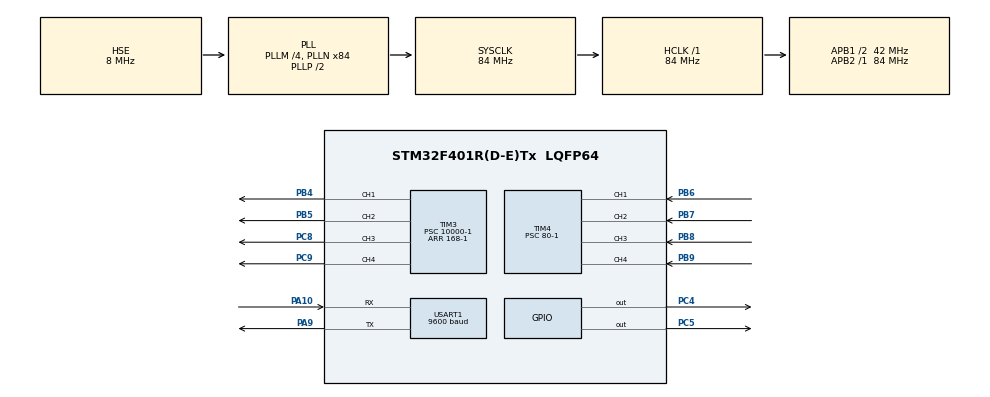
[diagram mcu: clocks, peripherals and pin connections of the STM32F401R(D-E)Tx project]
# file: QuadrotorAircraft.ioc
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Mcu.Family=STM32F4
Mcu.Name=STM32F401R(D-E)Tx
Mcu.Package=LQFP64
NVIC.PriorityGroup=NVIC_PRIORITYGROUP_4
NVIC.TIM4_IRQn=true\:0\:0\:false\:false\:true\:true\:true\:true
NVIC.USART1_IRQn=true\:0\:0\:false\:false\:true\:true\:true\:true
PA10.Mode=Asynchronous
PA10.Signal=USART1_RX
PA13.Mode=Serial_Wire
PA13.Signal=SYS_JTMS-SWDIO
PA14.Mode=Serial_Wire
PA14.Signal=SYS_JTCK-SWCLK
PA9.Mode=Asynchronous
PA9.Signal=USART1_TX
PB4.Signal=S_TIM3_CH1
PB5.Signal=S_TIM3_CH2
PB6.Signal=S_TIM4_CH1
PB7.Signal=S_TIM4_CH2
PB8.Signal=S_TIM4_CH3
PB9.Signal=S_TIM4_CH4
PC4.Signal=GPIO_Output
PC5.Signal=GPIO_Output
PC8.Signal=S_TIM3_CH3
PC9.Signal=S_TIM3_CH4
PH0\ -\ OSC_IN.Mode=HSE-External-Oscillator
PH0\ -\ OSC_IN.Signal=RCC_OSC_IN
PH1\ -\ OSC_OUT.Mode=HSE-External-Oscillator
PH1\ -\ OSC_OUT.Signal=RCC_OSC_OUT
ProjectManager.HeapSize=0x200
ProjectManager.StackSize=0x400
ProjectManager.TargetToolchain=MDK-ARM V5.32
RCC.48MHZClocksFreq_Value=42000000
RCC.AHBFreq_Value=84000000
RCC.APB1CLKDivider=RCC_HCLK_DIV2
RCC.APB1Freq_Value=42000000
RCC.APB1TimFreq_Value=84000000
RCC.APB2Freq_Value=84000000
RCC.APB2TimFreq_Value=84000000
RCC.CortexFreq_Value=84000000
RCC.HCLKFreq_Value=84000000
RCC.HSE_VALUE=8000000
RCC.HSI_VALUE=16000000
RCC.LSE_VALUE=32768
RCC.PLLM=4
RCC.PLLN=84
RCC.PLLSourceVirtual=RCC_PLLSOURCE_HSE
RCC.SYSCLKFreq_VALUE=84000000
RCC.SYSCLKSource=RCC_SYSCLKSOURCE_PLLCLK
RCC.VCOOutputFreq_Value=168000000
SH.S_TIM3_CH1.0=TIM3_CH1,PWM Generation1 CH1
SH.S_TIM3_CH2.0=TIM3_CH2,PWM Generation2 CH2
SH.S_TIM3_CH3.0=TIM3_CH3,PWM Generation3 CH3
SH.S_TIM3_CH4.0=TIM3_CH4,PWM Generation4 CH4
SH.S_TIM4_CH1.0=TIM4_CH1,Input_Capture1_from_TI1
SH.S_TIM4_CH2.0=TIM4_CH2,Input_Capture2_from_TI2
SH.S_TIM4_CH3.0=TIM4_CH3,Input_Capture3_from_TI3
SH.S_TIM4_CH4.0=TIM4_CH4,Input_Capture4_from_TI4
TIM3.Channel-PWM\ Generation1\ CH1=TIM_CHANNEL_1
TIM3.Channel-PWM\ Generation2\ CH2=TIM_CHANNEL_2
TIM3.Channel-PWM\ Generation3\ CH3=TIM_CHANNEL_3
TIM3.Channel-PWM\ Generation4\ CH4=TIM_CHANNEL_4
TIM3.Period=168-1
TIM3.Prescaler=10000-1
TIM4.Channel-Input_Capture1_from_TI1=TIM_CHANNEL_1
TIM4.Channel-Input_Capture2_from_TI2=TIM_CHANNEL_2
TIM4.Channel-Input_Capture3_from_TI3=TIM_CHANNEL_3
TIM4.Channel-Input_Capture4_from_TI4=TIM_CHANNEL_4
TIM4.Prescaler=80-1
USART1.BaudRate=9600
USART1.VirtualMode=VM_ASYNC
board=custom

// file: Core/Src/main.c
/* USER CODE BEGIN Header */
/**
  ******************************************************************************
  * @file           : main.c
  * @brief          : Main program body
  ******************************************************************************
  * @attention
  *
  * Copyright (c) 2024 STMicroelectronics.
  * All rights reserved.
  *
  * This software is licensed under terms that can be found in the LICENSE file
  * in the root directory of this software component.
  * If no LICENSE file comes with this software, it is provided AS-IS.
  *
  ******************************************************************************
  */
/* USER CODE END Header */
#include "main.h"
#include "tim.h"
#include "usart.h"
#include "gpio.h"

/* USER CODE BEGIN Includes */
#include "MySerial.h"
#include "MPU6050.h"
#include "Anonymity.h"
#include "AttitudeSolver.h"
#include "MadgWick.h"
#include "MyMadgWick.h"
#include "Motor.h"
#include "Receiver.h"
#include "UpdateMotorState.h"
#include "AttitudePIDController.h"

#include "tinyOS.h"
/* USER CODE END Includes */

/* USER CODE BEGIN PV */
extern quaternion q;
/* USER CODE END PV */

void SystemClock_Config(void);

tTask tTaskIdle;
tTaskStack idleTaskEnv[TINYOS_IDLETASK_STACK_SIZE];

void idleTaskEntry (void * param) {

#if TINYOS_ENABLE_CPUUSAGE_STATE == 1
    // 禁止调度，防止后面在创建任务时切换到其它任务中去
    tTaskSchedDisable();
#endif

    // 初始化App相关配置
    tInitApp();

#if TINYOS_ENABLE_TIMER == 1
    // 初始化定时器任务
    tTimerInitTask();
#endif

    // 启动系统时钟节拍
    tSetSysTickPeriod(TINYOS_SYSTICK_MS);

#if TINYOS_ENABLE_CPUUSAGE_STATE == 1
    // 等待与时钟同步
    cpuUsageSyncWithSysTick();
#endif

	  //外设初始化
		HAL_Init();
		SystemClock_Config();
		MX_GPIO_Init();
		MX_USART1_UART_Init();
		MX_TIM3_Init();
		MX_TIM4_Init();
		/* USER CODE BEGIN 2 */
		MySerial_Init();
    for (;;)
    {
#if TINYOS_ENABLE_CPUUSAGE_STATE == 1
        uint32_t status = tTaskEnterCritical();
        idleCount++;
        tTaskExitCritical(status);
#endif

#if TINYOS_ENABLE_HOOKS == 1
			tHooksCpuIdle();
#endif
    }
}

int main ()
{
		tTinyOSInit();
    // 创建空闲任务
    tTaskInit(&tTaskIdle, idleTaskEntry, (void *)0, TINYOS_PRIO_COUNT - 1, idleTaskEnv, TINYOS_IDLETASK_STACK_SIZE);
    tTinyOSStart();
    return 0;
}

void SystemClock_Config(void)
{
  RCC_OscInitTypeDef RCC_OscInitStruct = {0};
  RCC_ClkInitTypeDef RCC_ClkInitStruct = {0};

  /** Configure the main internal regulator output voltage
  */
  __HAL_RCC_PWR_CLK_ENABLE();
  __HAL_PWR_VOLTAGESCALING_CONFIG(PWR_REGULATOR_VOLTAGE_SCALE2);

  /** Initializes the RCC Oscillators according to the specified parameters
  * in the RCC_OscInitTypeDef structure.
  */
  RCC_OscInitStruct.OscillatorType = RCC_OSCILLATORTYPE_HSE;
  RCC_OscInitStruct.HSEState = RCC_HSE_ON;
  RCC_OscInitStruct.PLL.PLLState = RCC_PLL_ON;
  RCC_OscInitStruct.PLL.PLLSource = RCC_PLLSOURCE_HSE;
  RCC_OscInitStruct.PLL.PLLM = 4;
  RCC_OscInitStruct.PLL.PLLN = 84;
  RCC_OscInitStruct.PLL.PLLP = RCC_PLLP_DIV2;
  RCC_OscInitStruct.PLL.PLLQ = 4;
  if (HAL_RCC_OscConfig(&RCC_OscInitStruct) != HAL_OK)
  {
    Error_Handler();
  }

  /** Initializes the CPU, AHB and APB buses clocks
  */
  RCC_ClkInitStruct.ClockType = RCC_CLOCKTYPE_HCLK|RCC_CLOCKTYPE_SYSCLK
                              |RCC_CLOCKTYPE_PCLK1|RCC_CLOCKTYPE_PCLK2;
  RCC_ClkInitStruct.SYSCLKSource = RCC_SYSCLKSOURCE_PLLCLK;
  RCC_ClkInitStruct.AHBCLKDivider = RCC_SYSCLK_DIV1;
  RCC_ClkInitStruct.APB1CLKDivider = RCC_HCLK_DIV2;
  RCC_ClkInitStruct.APB2CLKDivider = RCC_HCLK_DIV1;

  if (HAL_RCC_ClockConfig(&RCC_ClkInitStruct, FLASH_LATENCY_2) != HAL_OK)
  {
    Error_Handler();
  }
}

void Error_Handler(void)
{
  __disable_irq();
  while (1)
  {
  }
}
